# cc13x2_cc26x2 register map
File version: 2.1
CPU: CM4 r0p1, little endian, MPU, FPU, 3 interrupt priority bits
Registers are 32-bit, read-write, reset 0x0 unless marked. A register's access mark holds for its fields unless they carry their own. Offsets are from the block's base; [hi:lo] are bit positions; {n}, {i} and the like mark numbered series.

## AUX_SYSIF — AUX System Interface (AUX_SYSIF) is responsible for: system resource requests, such as power supply, clock and, wakeup requests. configuration of AUX peripheral operational rates for AUX_SPIM, AUX_MAC, AUX_ANAIF DAC state machine and AUX_TIMER01. configuration of event synchronization rate for AUX_EVCTL:EVSTAT2 and AUX_EVCTL:EVSTAT3. configuration of AUX_SCE wakeup vectors that trigger AUX_SCE execution from sleep. eripheral operational rate for AUX modules mentioned above can either be: SCE rate, which is configured in AON_PMCTL:AUXSCECLK. AUX bus rate, which equals SCE rate or SCLK_HF divided by two when MCU domain is active or AUX operational mode is active. UX_SYSIF also interfaces AON_RTC and AON_BATMON to enable read access to data and sub-second increment control of AON_RTC.
Base 0x400C6000
0x00 OPMODEREQ — Operational Mode Request UX can operate in three operational modes. Each mode is associated with: a SCE clock source or rate, given by AON_PMCTL:AUXSCECLK. This rate is termed SCE_RATE. a system power supply state request. AUX can request powerdown (uLDO) or active (GLDO or DCDC) system power supply state. a specific system response to an active AUX wakeup flag. The response is dependent on what operational mode is requested. LDO power supply state offers limited current supply. AUX_SCE cannot use certain peripherals and functions such as AUX_DDI0_OSC, AUX_TDC and AUX_ANAIF ADC interface in this power supply state. ollow these rules: It is not allowed to change a request until it has been acknowledged through OPMODEACK. A change in mode request must happen stepwise along this sequence, the direction is irrelevant: PDA - A - LP - PDLP. ailure to follow these rules might result in unexpected behavior and must be avoided.
  [1:0] REQ
0x04 OPMODEACK ro — Operational Mode Acknowledgement UX_SCE program must assume that the current operational mode is the one acknowledged.
  [1:0] ACK
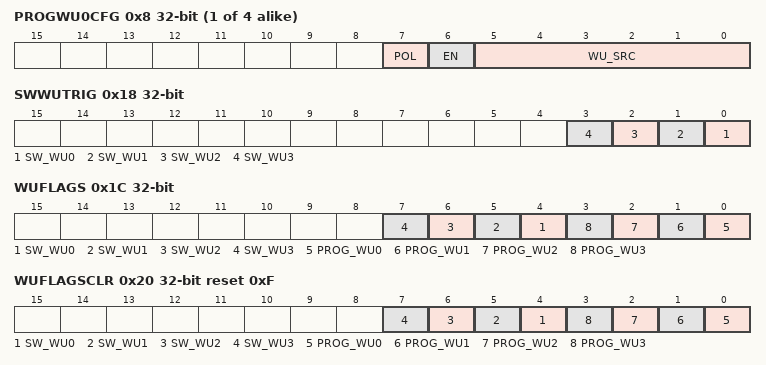
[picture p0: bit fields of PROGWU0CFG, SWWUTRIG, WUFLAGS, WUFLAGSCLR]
{0x8+4i} PROGWU{i}CFG (i=0..3) — Programmable Wakeup {i} Configuration onfigure this register to enable a customized AUX wakeup flag. The wakeup flag will be captured by AON_PMCTL which responds according to the current operational mode. You can select WUFLAGS.PROG_WU{i} to trigger execution of a programmable AUX_SCE vector by configuration of VECCFGn. You need to follow the procedure described in WUFLAGSCLR to clear this flag. You need to follow the procedure described in WUGATE to configure it.
  [7] POL, [6] EN, [5:0] WU_SRC
0x18 SWWUTRIG wo — Software Wakeup Triggers ystem CPU uses these wakeup flags to perform handshaking with AUX_SCE. The wakeup flags can change the operational mode of AUX and guarantees a non-zero SCE clock rate. AUX_SCE wakeup vectors are configured in VECCFGn.
  [n] SW_WU{n} (n=0..3)
0x1C WUFLAGS ro — Wakeup Flags his register holds the eight AUX wakeup flags. Each flag can cause AUX operational mode to change as given in OPMODEREQ. To clear flag n you must set bit n in WUFLAGSCLR until flag n is read as 0. You must clear bit n in WUFLAGSCLR before flag n can be set again.
  [n+4] SW_WU{n} (n=0..3), [n] PROG_WU{n} (n=0..3)
0x20 WUFLAGSCLR reset 0xF — Wakeup Flags Clear his register clears AUX wakeup flags WUFLAGS. o clear programmable wakeup flags you must disable the AUX wakeup output first. After the programmable wakeup flags are cleared you must re-enable the AUX wakeup output. Write WUGATE to disable or enable the AUX wakeup output. This procedure is not required when you want to clear a software-triggered wakeup.
  [n+4] SW_WU{n} (n=0..3), [n] PROG_WU{n} (n=0..3)
0x24 WUGATE — Wakeup Gate ou must disable the AUX wakeup output: Before you clear a programmable wakeup flag. Before you change the value of [PROGWUnCFG.EN] or [PROGWUnCFG.WU_SRC]. he AUX wakeup output must be re-enabled after clear operation or programmable wakeup configuration.
  [0] EN
{0x28+4i} VECCFG{i} (i=0..7) — Vector Configuration {i} UX_SCE wakeup vector {i} configuration
  [3:0] VEC_EV
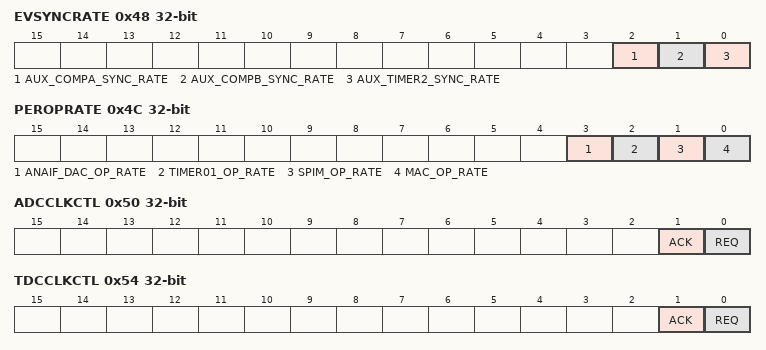
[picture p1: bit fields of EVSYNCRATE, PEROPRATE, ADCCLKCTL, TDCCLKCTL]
0x48 EVSYNCRATE — Event Synchronization Rate onfigure synchronization rate for certain events to the synchronous AUX event bus. ou must select SCE rate when AUX_SCE uses the event. You must select AUX bus rate when system CPU uses the event. CE rate equals rate configured in AON_PMCTL:AUXSCECLK. AUX bus rate equals SCE rate, or SCLK_HF divided by two when MCU domain is active.
  [2] AUX_COMPA_SYNC_RATE, [1] AUX_COMPB_SYNC_RATE, [0] AUX_TIMER2_SYNC_RATE
0x4C PEROPRATE — Peripheral Operational Rate ome AUX peripherals are operated at either SCE or at AUX bus rate. ou must select SCE rate when AUX_SCE uses such peripheral or an event produced by it. You must select AUX bus rate when system CPU uses such peripheral. CE rate equals rate configured in AON_PMCTL:AUXSCECLK. AUX bus rate equals SCE rate, or SCLK_HF divided by 2 when MCU domain is active.
  [3] ANAIF_DAC_OP_RATE, [2] TIMER01_OP_RATE, [1] SPIM_OP_RATE, [0] MAC_OP_RATE
0x50 ADCCLKCTL — ADC Clock Control
  [1] ACK, [0] REQ
0x54 TDCCLKCTL — TDC Counter Clock Control ontrols if the AUX_TDC counter clock source is enabled. TDC counter clock source is configured in DDI_0_OSC:CTL0.ACLK_TDC_SRC_SEL.
  [1] ACK, [0] REQ
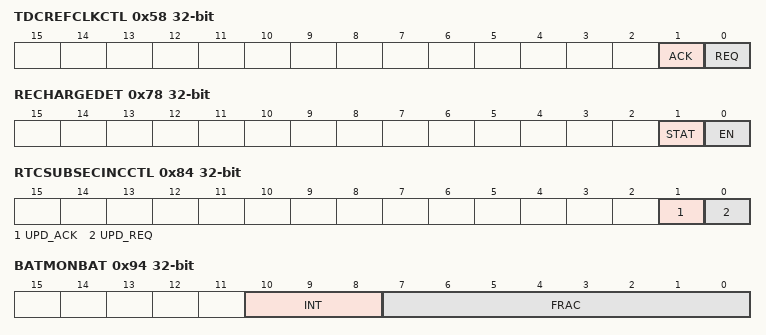
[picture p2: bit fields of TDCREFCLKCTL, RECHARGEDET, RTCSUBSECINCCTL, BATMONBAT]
0x58 TDCREFCLKCTL — TDC Reference Clock Control ontrols if the AUX_TDC reference clock source is enabled. This clock is compared against the AUX_TDC counter clock. TDC reference clock source is configured in DDI_0_OSC:CTL0.ACLK_REF_SRC_SEL.
  [1] ACK, [0] REQ
0x5C TIMER2CLKCTL — AUX_TIMER2 Clock Control ccess to AUX_TIMER2 is only possible when TIMER2CLKSTAT.STAT is different from NONE.
  [2:0] SRC
0x60 TIMER2CLKSTAT ro — AUX_TIMER2 Clock Status
  [2:0] STAT
0x64 TIMER2CLKSWITCH ro reset 0x1 — AUX_TIMER2 Clock Switch
  [0] RDY
0x68 TIMER2DBGCTL — AUX_TIMER2 Debug Control
  [0] DBG_FREEZE_EN
0x70 CLKSHIFTDET reset 0x1 — Clock Shift Detection transition in the MCU domain state causes a non-accumulative change to the SCE clock period when the AUX clock rate is derived from SCLK_MF or SCLK_LF: A single SCE clock cycle is 6 thru 8 SCLK_HF cycles longer when MCU domain enters active state. A single SCE clock cycle is 6 thru 8 SCLK_HF cycles shorter when MCU domain exits active state. UX_SCE detects if such events occurred to the SCE clock during the time period between a clear of STAT and a read of STAT.
  [0] STAT
0x74 RECHARGETRIG — VDDR Recharge Trigger
  [0] TRIG
0x78 RECHARGEDET — VDDR Recharge Detection ome applications can be sensitive to power noise caused by recharge of VDDR. You can detect if VDDR recharge occurs.
  [1] STAT, [0] EN
0x7C RTCSUBSECINC0 — Real Time Counter Sub Second Increment 0 NC15_0 will replace bits 15:0 in AON_RTC:SUBSECINC when RTCSUBSECINCCTL.UPD_REQ is set.
  [15:0] INC15_0
0x80 RTCSUBSECINC1 — Real Time Counter Sub Second Increment 1 NC23_16 will replace bits 23:16 in AON_RTC:SUBSECINC when RTCSUBSECINCCTL.UPD_REQ is set.
  [7:0] INC23_16
0x84 RTCSUBSECINCCTL — Real Time Counter Sub Second Increment Control
  [1] UPD_ACK, [0] UPD_REQ
0x88 RTCSEC ro — Real Time Counter Second ystem CPU must not access this register. Instead, system CPU must access AON_RTC:SEC.VALUE directly.
  [15:0] SEC
0x8C RTCSUBSEC ro — Real Time Counter Sub-Second ystem CPU must not access this register. Instead, system CPU must access AON_RTC:SUBSEC.VALUE directly.
  [15:0] SUBSEC
0x90 RTCEVCLR — AON_RTC Event Clear equest to clear events: AON_RTC:EVFLAGS.CH2. AON_RTC:EVFLAGS.CH2 delayed version. AUX_EVCTL:EVSTAT2.AON_RTC_CH2. AUX_EVCTL:EVSTAT2.AON_RTC_CH2_DLY.
  [0] RTC_CH2_EV_CLR
0x94 BATMONBAT ro — AON_BATMON Battery Voltage Value ead access to AON_BATMON:BAT. System CPU must not access this register. Instead, system CPU must access AON_BATMON:BAT directly. AON_BATMON:BAT updates during VDDR recharge or active operational mode.
  [10:8] INT, [7:0] FRAC
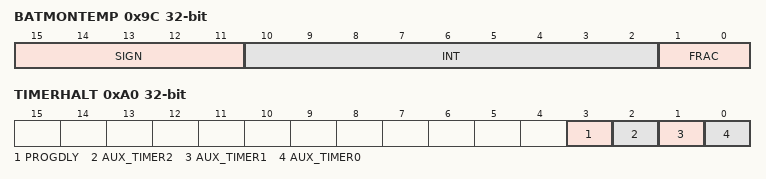
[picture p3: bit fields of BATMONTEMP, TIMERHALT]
0x9C BATMONTEMP ro — AON_BATMON Temperature Value ead access to AON_BATMON:TEMP. System CPU must not access this register. Instead, system CPU must access AON_BATMON:TEMP directly. AON_BATMON:TEMP updates during VDDR recharge or active operational mode.
  [15:11] SIGN, [10:2] INT, [1:0] FRAC
0xA0 TIMERHALT — Timer Halt ebug register
  [3] PROGDLY, [2] AUX_TIMER2, [1] AUX_TIMER1, [0] AUX_TIMER0
0xB0 TIMER2BRIDGE ro — AUX_TIMER2 Bridge
  [0] BUSY
0xB4 SWPWRPROF — Software Power Profiler
  [2:0] STAT
